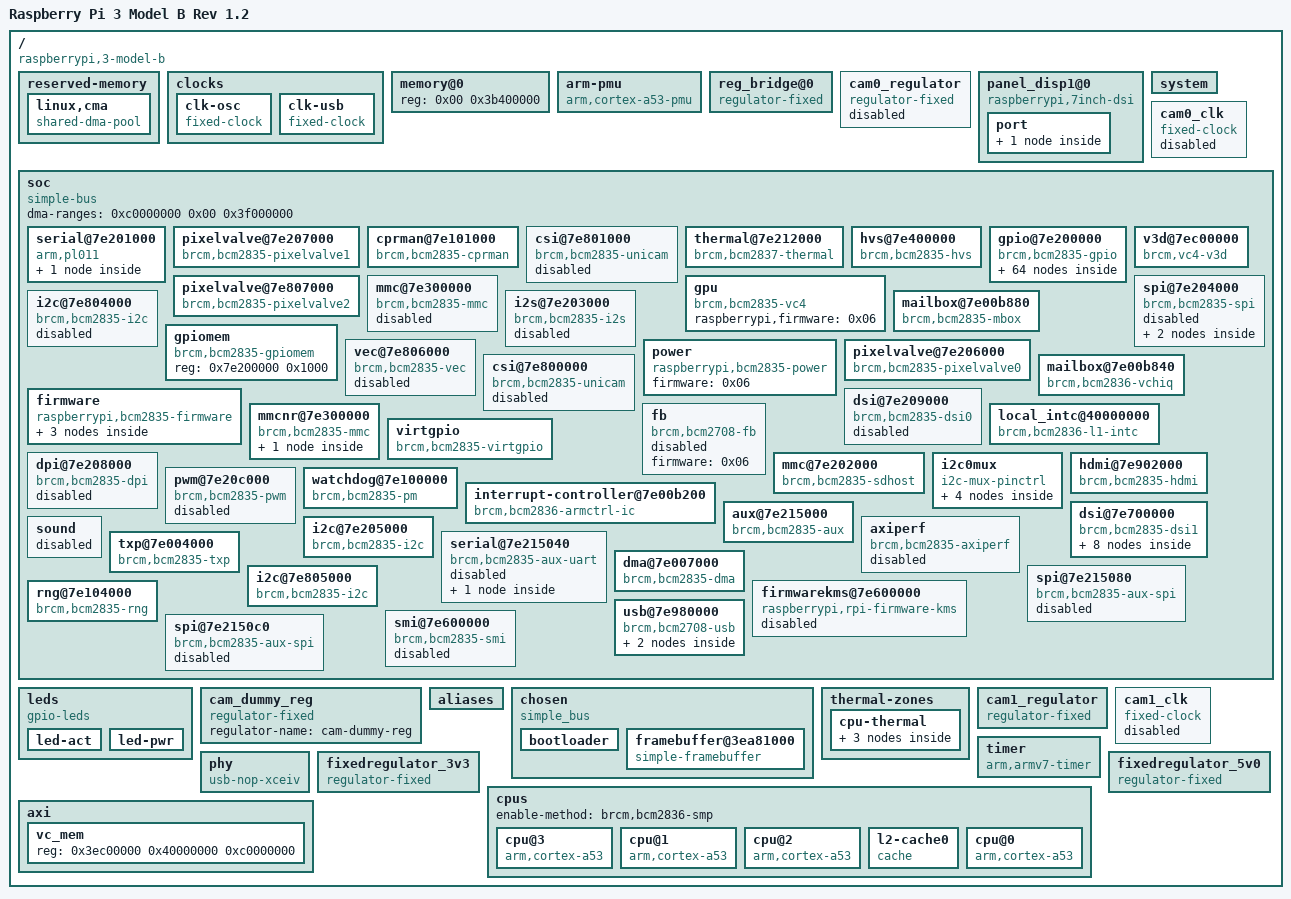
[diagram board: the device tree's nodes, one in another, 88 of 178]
/dts-v1/;

/ {
	compatible = "raspberrypi,3-model-b\0brcm,bcm2837";
	serial-number = "0000000004c159e7";
	model = "Raspberry Pi 3 Model B Rev 1.2";
	memreserve = <0x3b400000 0x4c00000>;
	interrupt-parent = <0x01>;
	#address-cells = <0x01>;
	#size-cells = <0x01>;

	reserved-memory {
		ranges;
		#address-cells = <0x01>;
		#size-cells = <0x01>;
		phandle = <0x38>;

		linux,cma {
			reusable;
			compatible = "shared-dma-pool";
			size = <0x10000000>;
			phandle = <0x39>;
			linux,cma-default;
		};
	};

	clocks {

		clk-osc {
			compatible = "fixed-clock";
			#clock-cells = <0x00>;
			phandle = <0x03>;
			clock-output-names = "osc";
			clock-frequency = <0x124f800>;
		};

		clk-usb {
			compatible = "fixed-clock";
			#clock-cells = <0x00>;
			phandle = <0x16>;
			clock-output-names = "otg";
			clock-frequency = <0x1c9c3800>;
		};
	};

	memory@0 {
		device_type = "memory";
		reg = <0x00 0x3b400000>;
	};

	__overrides__ {
		pwr_led_gpio = "\0\0\06gpios:4";
		cam0-led-ctrl;
		i2c1 = "\0\0\0+status";
		i2c_vc = [00 00 00 1c 73 74 61 74 75 73 00 00 00 00 2a 73 74 61 74 75 73 00];
		sd_overclock = "\0\0\0.brcm,overclock-50:0";
		sdio_overclock = "\0\0\0/brcm,overclock-50:0\0\0\0\00brcm,overclock-50:0";
		i2c0_baudrate = [00 00 00 1c 63 6c 6f 63 6b 2d 66 72 65 71 75 65 6e 63 79 3a 30 00];
		sd_pio_limit = "\0\0\0.brcm,pio-limit:0";
		act_led_trigger = "\0\0\05linux,default-trigger";
		audio = "\0\0\04bootargs{on='snd_bcm2835.enable_headphones=1 snd_bcm2835.enable_hdmi=1',off='snd_bcm2835.enable_headphones=0 snd_bcm2835.enable_hdmi=0'}";
		sd_debug = "\0\0\0.brcm,debug";
		cam0-pwdn-ctrl;
		cache_line_size;
		cam0-led;
		i2c1_baudrate = "\0\0\0+clock-frequency:0";
		spi = "\0\0\0)status";
		i2c_arm = "\0\0\0+status";
		sd = "\0\0\0.status";
		pwr_led_activelow = "\0\0\06gpios:8";
		uart0 = "\0\0\0&status";
		i2c2_iknowwhatimdoing = [00 00 00 1a 73 74 61 74 75 73 00];
		i2s = "\0\0\0(status";
		i2c0 = [00 00 00 1c 73 74 61 74 75 73 00 00 00 00 2a 73 74 61 74 75 73 00];
		arm_freq = "\0\0\0\"clock-frequency:0\0\0\0\0#clock-frequency:0\0\0\0\0$clock-frequency:0\0\0\0\0%clock-frequency:0";
		watchdog = "\0\0\0,status";
		krnbt = "\0\0\03status";
		i2c_baudrate = "\0\0\0+clock-frequency:0";
		i2c_vc_baudrate = [00 00 00 1c 63 6c 6f 63 6b 2d 66 72 65 71 75 65 6e 63 79 3a 30 00];
		sd_poll_once = "\0\0\0.non-removable?";
		axiperf = "\0\0\01status";
		act_led_activelow = "\0\0\05gpios:8";
		i2c2_baudrate = [00 00 00 1a 63 6c 6f 63 6b 2d 66 72 65 71 75 65 6e 63 79 3a 30 00];
		krnbt_baudrate = "\0\0\03max-speed:0";
		sd_force_pio = "\0\0\0.brcm,force-pio?";
		pwr_led_trigger = "\0\0\06linux,default-trigger";
		hdmi = "\0\0\02status";
		cam0-pwdn;
		uart1 = "\0\0\0'status";
		i2c_arm_baudrate = "\0\0\0+clock-frequency:0";
		random = "\0\0\0-status";
		act_led_gpio = "\0\0\05gpios:4";
		i2c = "\0\0\0+status";
	};

	arm-pmu {
		compatible = "arm,cortex-a53-pmu\0arm,cortex-a7-pmu";
		interrupt-parent = <0x18>;
		interrupts = <0x09 0x04>;
	};

	reg_bridge@0 {
		compatible = "regulator-fixed";
		enable-active-high;
		gpio = <0x9c 0x00 0x00>;
		phandle = <0x99>;
		vin-supply = <0x9c>;
		reg = <0x00>;
		regulator-name = "bridge_reg";
	};

	cam0_regulator {
		compatible = "regulator-fixed";
		enable-active-high;
		status = "disabled";
		phandle = <0x90>;
		regulator-name = "cam0-reg";
	};

	panel_disp1@0 {
		compatible = "raspberrypi,7inch-dsi\0simple-panel";
		phandle = <0x9e>;
		reg = <0x00>;
		backlight = <0x9c>;
		power-supply = <0x9c>;

		port {

			endpoint {
				remote-endpoint = <0x9d>;
				phandle = <0x9b>;
			};
		};
	};

	system {
		linux,serial = <0x00 0x4c159e7>;
		linux,revision = <0xa02082>;
	};

	__symbols__ {
		uart0_gpio14 = "/soc/gpio@7e200000/uart0_gpio14";
		pwm = "/soc/pwm@7e20c000";
		gpclk1_gpio5 = "/soc/gpio@7e200000/gpclk1_gpio5";
		clk_usb = "/clocks/clk-usb";
		pixelvalve0 = "/soc/pixelvalve@7e206000";
		minibt = "/soc/serial@7e215040/bluetooth";
		uart0_ctsrts_gpio30 = "/soc/gpio@7e200000/uart0_ctsrts_gpio30";
		uart1_ctsrts_gpio16 = "/soc/gpio@7e200000/uart1_ctsrts_gpio16";
		uart0_gpio32 = "/soc/gpio@7e200000/uart0_gpio32";
		intc = "/soc/interrupt-controller@7e00b200";
		spi2 = "/soc/spi@7e2150c0";
		i2c0if = "/soc/i2c@7e205000";
		jtag_gpio4 = "/soc/gpio@7e200000/jtag_gpio4";
		dsi1 = "/soc/dsi@7e700000";
		clocks = "/soc/cprman@7e101000";
		i2c1 = "/soc/i2c@7e804000";
		i2c_vc = "/soc/i2c0mux/i2c@0";
		alt0 = "/soc/gpio@7e200000/alt0";
		firmwarekms = "/soc/firmwarekms@7e600000";
		smi = "/soc/smi@7e600000";
		uart1_ctsrts_gpio42 = "/soc/gpio@7e200000/uart1_ctsrts_gpio42";
		spi0 = "/soc/spi@7e204000";
		bt = "/soc/serial@7e201000/bluetooth";
		thermal = "/soc/thermal@7e212000";
		vdd_5v0_reg = "/fixedregulator_5v0";
		vchiq = "/soc/mailbox@7e00b840";
		sdhost = "/soc/mmc@7e202000";
		aux = "/soc/aux@7e215000";
		cam0_regulator = "/cam0_regulator";
		gpio = "/soc/gpio@7e200000";
		gpclk0_gpio4 = "/soc/gpio@7e200000/gpclk0_gpio4";
		pwm0_gpio12 = "/soc/gpio@7e200000/pwm0_gpio12";
		pwm1_gpio19 = "/soc/gpio@7e200000/pwm1_gpio19";
		sdhci = "/soc/mmc@7e300000";
		pwm0_gpio40 = "/soc/gpio@7e200000/pwm0_gpio40";
		gpclk2_gpio43 = "/soc/gpio@7e200000/gpclk2_gpio43";
		cam1_reg = "/cam1_regulator";
		dpi = "/soc/dpi@7e208000";
		dpi_18bit_cpadhi_gpio2 = "/soc/gpio@7e200000/dpi_18bit_cpadhi_gpio2";
		v3d = "/soc/v3d@7ec00000";
		vdd_3v3_reg = "/fixedregulator_3v3";
		uart1_ctsrts_gpio30 = "/soc/gpio@7e200000/uart1_ctsrts_gpio30";
		gpioout = "/soc/gpio@7e200000/gpioout";
		dma = "/soc/dma@7e007000";
		spidev1 = "/soc/spi@7e204000/spidev@1";
		mmcnr = "/soc/mmcnr@7e300000";
		spi0_gpio35 = "/soc/gpio@7e200000/spi0_gpio35";
		vc4 = "/soc/gpu";
		firmware_clocks = "/soc/firmware/clocks";
		pwm1_gpio45 = "/soc/gpio@7e200000/pwm1_gpio45";
		cpu3 = "/cpus/cpu@3";
		dpi_18bit_cpadhi_gpio0 = "/soc/gpio@7e200000/dpi_18bit_cpadhi_gpio0";
		cam0_clk = "/cam0_clk";
		pcm_gpio28 = "/soc/gpio@7e200000/pcm_gpio28";
		dpi_gpio0 = "/soc/gpio@7e200000/dpi_gpio0";
		power = "/soc/power";
		soc = "/soc";
		i2c0_gpio0 = "/soc/gpio@7e200000/i2c0_gpio0";
		pcm_gpio18 = "/soc/gpio@7e200000/pcm_gpio18";
		leds = "/leds";
		thermal_trips = "/thermal-zones/cpu-thermal/trips";
		csi1 = "/soc/csi@7e801000";
		i2s_pins = "/soc/gpio@7e200000/i2s";
		cam_dummy_reg = "/cam_dummy_reg";
		firmware = "/soc/firmware";
		cpu1 = "/cpus/cpu@1";
		mmc = "/soc/mmc@7e300000";
		l2 = "/cpus/l2-cache0";
		dpi_18bit_gpio2 = "/soc/gpio@7e200000/dpi_18bit_gpio2";
		usbphy = "/phy";
		pixelvalve1 = "/soc/pixelvalve@7e207000";
		spi = "/soc/spi@7e204000";
		spi0_pins = "/soc/gpio@7e200000/spi0_pins";
		i2c_arm = "/soc/i2c@7e804000";
		chosen = "/chosen";
		clk_osc = "/clocks/clk-osc";
		ethernet = "/soc/usb@7e980000/usb1@1/ethernet@1";
		uart0 = "/soc/serial@7e201000";
		pwm1_gpio13 = "/soc/gpio@7e200000/pwm1_gpio13";
		i2c1_pins = "/soc/gpio@7e200000/i2c1";
		rmem = "/reserved-memory";
		cpu_thermal = "/thermal-zones/cpu-thermal";
		fb = "/soc/fb";
		pwm1_gpio41 = "/soc/gpio@7e200000/pwm1_gpio41";
		txp = "/soc/txp@7e004000";
		dpi_18bit_gpio0 = "/soc/gpio@7e200000/dpi_18bit_gpio0";
		spi0_gpio7 = "/soc/gpio@7e200000/spi0_gpio7";
		i2c2 = "/soc/i2c@7e805000";
		uart1_pins = "/soc/gpio@7e200000/uart1_pins";
		i2c1_gpio44 = "/soc/gpio@7e200000/i2c1_gpio44";
		cma = "/reserved-memory/linux,cma";
		i2c0_gpio28 = "/soc/gpio@7e200000/i2c0_gpio28";
		i2c_slave_gpio18 = "/soc/gpio@7e200000/i2c_slave_gpio18";
		cam1_clk = "/cam1_clk";
		i2s = "/soc/i2s@7e203000";
		emmc_gpio48 = "/soc/gpio@7e200000/emmc_gpio48";
		spi1 = "/soc/spi@7e215080";
		virtgpio = "/soc/virtgpio";
		usb = "/soc/usb@7e980000";
		dsi0 = "/soc/dsi@7e209000";
		i2c1_gpio2 = "/soc/gpio@7e200000/i2c1_gpio2";
		expgpio = "/soc/firmware/expgpio";
		uart0_ctsrts_gpio38 = "/soc/gpio@7e200000/uart0_ctsrts_gpio38";
		pm = "/soc/watchdog@7e100000";
		audio_pins = "/soc/gpio@7e200000/audio_pins";
		i2c0 = "/soc/i2c0mux/i2c@0";
		brcmf = "/soc/mmcnr@7e300000/wifi@1";
		spi1_gpio16 = "/soc/gpio@7e200000/spi1_gpio16";
		i2c0mux = "/soc/i2c0mux";
		i2c_csi_dsi = "/soc/i2c0mux/i2c@1";
		i2c0_pins = "/soc/gpio@7e200000/i2c0";
		pwr_led = "/leds/led-pwr";
		watchdog = "/soc/watchdog@7e100000";
		jtag_gpio22 = "/soc/gpio@7e200000/jtag_gpio22";
		spi2_gpio40 = "/soc/gpio@7e200000/spi2_gpio40";
		uart0_pins = "/soc/gpio@7e200000/uart0_pins";
		vec = "/soc/vec@7e806000";
		local_intc = "/soc/local_intc@40000000";
		i2c0_gpio44 = "/soc/gpio@7e200000/i2c0_gpio44";
		axiperf = "/soc/axiperf";
		spi0_cs_pins = "/soc/gpio@7e200000/spi0_cs_pins";
		sound = "/soc/sound";
		hvs = "/soc/hvs@7e400000";
		uart0_ctsrts_gpio16 = "/soc/gpio@7e200000/uart0_ctsrts_gpio16";
		act_led = "/leds/led-act";
		gpclk2_gpio6 = "/soc/gpio@7e200000/gpclk2_gpio6";
		spidev0 = "/soc/spi@7e204000/spidev@0";
		sdhost_gpio48 = "/soc/gpio@7e200000/sdhost_gpio48";
		bt_pins = "/soc/gpio@7e200000/bt_pins";
		dpi_16bit_gpio2 = "/soc/gpio@7e200000/dpi_16bit_gpio2";
		emmc_gpio34 = "/soc/gpio@7e200000/emmc_gpio34";
		gpclk1_gpio44 = "/soc/gpio@7e200000/gpclk1_gpio44";
		uart1_gpio14 = "/soc/gpio@7e200000/uart1_gpio14";
		cooling_maps = "/thermal-zones/cpu-thermal/cooling-maps";
		uart0_gpio36 = "/soc/gpio@7e200000/uart0_gpio36";
		sdio_pins = "/soc/gpio@7e200000/sdio_pins";
		dpi_16bit_cpadhi_gpio2 = "/soc/gpio@7e200000/dpi_16bit_cpadhi_gpio2";
		cpus = "/cpus";
		cpu2 = "/cpus/cpu@2";
		uart1_gpio32 = "/soc/gpio@7e200000/uart1_gpio32";
		hdmi = "/soc/hdmi@7e902000";
		pixelvalve2 = "/soc/pixelvalve@7e807000";
		pwm0_gpio18 = "/soc/gpio@7e200000/pwm0_gpio18";
		dpi_16bit_gpio0 = "/soc/gpio@7e200000/dpi_16bit_gpio0";
		gpclk1_gpio42 = "/soc/gpio@7e200000/gpclk1_gpio42";
		mailbox = "/soc/mailbox@7e00b880";
		uart1_gpio40 = "/soc/gpio@7e200000/uart1_gpio40";
		emmc_gpio22 = "/soc/gpio@7e200000/emmc_gpio22";
		uart1 = "/soc/serial@7e215040";
		dpi_16bit_cpadhi_gpio0 = "/soc/gpio@7e200000/dpi_16bit_cpadhi_gpio0";
		csi0 = "/soc/csi@7e800000";
		cam0_reg = "/cam_dummy_reg";
		random = "/soc/rng@7e104000";
		i2c = "/soc/i2c@7e804000";
		cpu0 = "/cpus/cpu@0";
		vcio = "/soc/firmware/vcio";
	};

	cam0_clk {
		compatible = "fixed-clock";
		status = "disabled";
		#clock-cells = <0x00>;
		phandle = <0x91>;
	};

	soc {
		compatible = "simple-bus";
		ranges = <0x7e000000 0x3f000000 0x1000000 0x40000000 0x40000000 0x1000>;
		#address-cells = <0x01>;
		#size-cells = <0x01>;
		phandle = <0x3d>;
		dma-ranges = <0xc0000000 0x00 0x3f000000>;

		serial@7e201000 {
			compatible = "arm,pl011\0arm,primecell";
			clocks = <0x08 0x13 0x08 0x14>;
			clock-names = "uartclk\0apb_pclk";
			status = "okay";
			interrupts = <0x02 0x19>;
			skip-init;
			phandle = <0x26>;
			arm,primecell-periphid = <0x241011>;
			reg = <0x7e201000 0x200>;
			pinctrl-0 = <0x09 0x0a>;
			cts-event-workaround;
			pinctrl-names = "default";

			bluetooth {
				compatible = "brcm,bcm43438-bt";
				shutdown-gpios = <0x0b 0x00 0x00>;
				max-speed = <0xe1000>;
				status = "disabled";
				phandle = <0x33>;
			};
		};

		pixelvalve@7e207000 {
			compatible = "brcm,bcm2835-pixelvalve1";
			status = "okay";
			interrupts = <0x02 0x0e>;
			phandle = <0x7d>;
			reg = <0x7e207000 0x100>;
		};

		cprman@7e101000 {
			compatible = "brcm,bcm2835-cprman";
			clocks = <0x03 0x04 0x00 0x04 0x01 0x04 0x02 0x05 0x00 0x05 0x01 0x05 0x02>;
			firmware = <0x06>;
			#clock-cells = <0x01>;
			phandle = <0x08>;
			claim-clocks = <0x22 0x23 0x0f 0x10>;
			reg = <0x7e101000 0x2000>;
		};

		csi@7e801000 {
			power-domains = <0x11 0x0d>;
			compatible = "brcm,bcm2835-unicam";
			clocks = <0x08 0x2e 0x19 0x04>;
			clock-names = "lp\0vpu";
			status = "disabled";
			#address-cells = <0x01>;
			interrupts = <0x02 0x07>;
			brcm,num-data-lanes = <0x02>;
			#size-cells = <0x00>;
			#clock-cells = <0x01>;
			phandle = <0x86>;
			reg = <0x7e801000 0x800 0x7e802004 0x04>;
		};

		thermal@7e212000 {
			compatible = "brcm,bcm2837-thermal";
			clocks = <0x08 0x1b>;
			#thermal-sensor-cells = <0x00>;
			status = "okay";
			phandle = <0x02>;
			reg = <0x7e212000 0x08>;
		};

		hvs@7e400000 {
			compatible = "brcm,bcm2835-hvs";
			status = "okay";
			interrupts = <0x02 0x01>;
			phandle = <0x79>;
			reg = <0x7e400000 0x6000>;
		};

		gpio@7e200000 {
			compatible = "brcm,bcm2835-gpio";
			gpio-line-names = "ID_SDA\0ID_SCL\0SDA1\0SCL1\0GPIO_GCLK\0GPIO5\0GPIO6\0SPI_CE1_N\0SPI_CE0_N\0SPI_MISO\0SPI_MOSI\0SPI_SCLK\0GPIO12\0GPIO13\0TXD1\0RXD1\0GPIO16\0GPIO17\0GPIO18\0GPIO19\0GPIO20\0GPIO21\0GPIO22\0GPIO23\0GPIO24\0GPIO25\0GPIO26\0GPIO27\0NC\0LAN_RUN_BOOT\0CTS0\0RTS0\0TXD0\0RXD0\0SD1_CLK\0SD1_CMD\0SD1_DATA0\0SD1_DATA1\0SD1_DATA2\0SD1_DATA3\0PWM0_OUT\0PWM1_OUT\0ETH_CLK\0WIFI_CLK\0SDA0\0SCL0\0SMPS_SCL\0SMPS_SDA\0SD_CLK_R\0SD_CMD_R\0SD_DATA0_R\0SD_DATA1_R\0SD_DATA2_R\0SD_DATA3_R";
			gpio-controller;
			gpio-ranges = <0x07 0x00 0x00 0x36>;
			#interrupt-cells = <0x02>;
			interrupts = <0x02 0x11 0x02 0x12>;
			phandle = <0x07>;
			reg = <0x7e200000 0xb4>;
			#gpio-cells = <0x02>;
			pinctrl-names = "default";
			interrupt-controller;

			uart0_gpio14 {
				brcm,pins = <0x0e 0x0f>;
				phandle = <0x52>;
				brcm,function = <0x04>;
			};

			gpclk1_gpio5 {
				brcm,pins = <0x05>;
				phandle = <0x43>;
				brcm,function = <0x04>;
			};

			uart0_ctsrts_gpio30 {
				brcm,pins = <0x1e 0x1f>;
				phandle = <0x54>;
				brcm,pull = <0x02 0x00>;
				brcm,function = <0x07>;
			};

			uart1_ctsrts_gpio16 {
				brcm,pins = <0x10 0x11>;
				phandle = <0x59>;
				brcm,function = <0x02>;
			};

			uart0_gpio32 {
				brcm,pins = <0x20 0x21>;
				phandle = <0x55>;
				brcm,pull = <0x00 0x02>;
				brcm,function = <0x07>;
			};

			jtag_gpio4 {
				brcm,pins = <0x04 0x05 0x06 0x0c 0x0d>;
				phandle = <0x5f>;
				brcm,function = <0x02>;
			};

			i2c1 {
				brcm,pins = <0x02 0x03>;
				phandle = <0x15>;
				brcm,function = <0x04>;
			};

			alt0 {
				brcm,pins = <0x04 0x05 0x07 0x08 0x09 0x0a 0x0b>;
				phandle = <0x70>;
				brcm,function = <0x04>;
			};

			uart1_ctsrts_gpio42 {
				brcm,pins = <0x2a 0x2b>;
				phandle = <0x5d>;
				brcm,function = <0x02>;
			};

			gpclk0_gpio4 {
				brcm,pins = <0x04>;
				phandle = <0x42>;
				brcm,function = <0x04>;
			};

			pwm0_gpio12 {
				brcm,pins = <0x0c>;
				phandle = <0x60>;
				brcm,function = <0x04>;
			};

			pwm1_gpio19 {
				brcm,pins = <0x13>;
				phandle = <0x64>;
				brcm,function = <0x02>;
			};

			pwm0_gpio40 {
				brcm,pins = <0x28>;
				phandle = <0x62>;
				brcm,function = <0x04>;
			};

			gpclk2_gpio43 {
				brcm,pins = <0x2b>;
				phandle = <0x47>;
				brcm,pull = <0x00>;
				brcm,function = <0x04>;
			};

			dpi_18bit_cpadhi_gpio2 {
				brcm,pins = <0x02 0x03 0x04 0x05 0x06 0x07 0x08 0x09 0x0c 0x0d 0x0e 0x0f 0x10 0x11 0x14 0x15 0x16 0x17 0x18 0x19>;
				phandle = <0x68>;
				brcm,function = <0x06>;
			};

			uart1_ctsrts_gpio30 {
				brcm,pins = <0x1e 0x1f>;
				phandle = <0x5b>;
				brcm,function = <0x02>;
			};

			gpioout {
				brcm,pins = <0x06>;
				phandle = <0x6f>;
				brcm,function = <0x01>;
			};

			spi0_gpio35 {
				brcm,pins = <0x23 0x24 0x25 0x26 0x27>;
				phandle = <0x4f>;
				brcm,function = <0x04>;
			};

			pwm1_gpio45 {
				brcm,pins = <0x2d>;
				phandle = <0x66>;
				brcm,function = <0x04>;
			};

			dpi_18bit_cpadhi_gpio0 {
				brcm,pins = <0x00 0x01 0x02 0x03 0x04 0x05 0x06 0x07 0x08 0x09 0x0c 0x0d 0x0e 0x0f 0x10 0x11 0x14 0x15 0x16 0x17 0x18 0x19>;
				phandle = <0x67>;
				brcm,pull = <0x00>;
				brcm,function = <0x06>;
			};

			pcm_gpio28 {
				brcm,pins = <0x1c 0x1d 0x1e 0x1f>;
				phandle = <0x4d>;
				brcm,function = <0x06>;
			};

			dpi_gpio0 {
				brcm,pins = <0x00 0x01 0x02 0x03 0x04 0x05 0x06 0x07 0x08 0x09 0x0a 0x0b 0x0c 0x0d 0x0e 0x0f 0x10 0x11 0x12 0x13 0x14 0x15 0x16 0x17 0x18 0x19 0x1a 0x1b>;
				phandle = <0x3f>;
				brcm,function = <0x06>;
			};

			i2c0_gpio0 {
				brcm,pins = <0x00 0x01>;
				phandle = <0x1d>;
				brcm,function = <0x04>;
			};

			pcm_gpio18 {
				brcm,pins = <0x12 0x13 0x14 0x15>;
				phandle = <0x4c>;
				brcm,function = <0x04>;
			};

			dpi_18bit_gpio2 {
				brcm,pins = <0x02 0x03 0x04 0x05 0x06 0x07 0x08 0x09 0x0a 0x0b 0x0c 0x0d 0x0e 0x0f 0x10 0x11 0x12 0x13 0x14 0x15>;
				phandle = <0x6a>;
				brcm,function = <0x06>;
			};

			spi0_pins {
				brcm,pins = <0x09 0x0a 0x0b>;
				phandle = <0x0f>;
				brcm,function = <0x04>;
			};

			pwm1_gpio13 {
				brcm,pins = <0x0d>;
				phandle = <0x63>;
				brcm,function = <0x04>;
			};

			pwm1_gpio41 {
				brcm,pins = <0x29>;
				phandle = <0x65>;
				brcm,function = <0x04>;
			};

			dpi_18bit_gpio0 {
				brcm,pins = <0x00 0x01 0x02 0x03 0x04 0x05 0x06 0x07 0x08 0x09 0x0a 0x0b 0x0c 0x0d 0x0e 0x0f 0x10 0x11 0x12 0x13 0x14 0x15>;
				phandle = <0x69>;
				brcm,function = <0x06>;
			};

			spi0_gpio7 {
				brcm,pins = <0x07 0x08 0x09 0x0a 0x0b>;
				phandle = <0x4e>;
				brcm,function = <0x04>;
			};

			uart1_pins {
				brcm,pins;
				phandle = <0x13>;
				brcm,pull;
				brcm,function;
			};

			i2c1_gpio44 {
				brcm,pins = <0x2c 0x2d>;
				phandle = <0x4a>;
				brcm,function = <0x06>;
			};

			i2c0_gpio28 {
				brcm,pins = <0x1c 0x1d>;
				phandle = <0x48>;
				brcm,function = <0x04>;
			};

			i2c_slave_gpio18 {
				brcm,pins = <0x12 0x13 0x14 0x15>;
				phandle = <0x5e>;
				brcm,function = <0x07>;
			};

			i2s {
				brcm,pins = <0x12 0x13 0x14 0x15>;
				phandle = <0x0e>;
				brcm,function = <0x04>;
			};

			emmc_gpio48 {
				brcm,pins = <0x30 0x31 0x32 0x33 0x34 0x35>;
				phandle = <0x14>;
				brcm,function = <0x07>;
			};

			i2c1_gpio2 {
				brcm,pins = <0x02 0x03>;
				phandle = <0x49>;
				brcm,function = <0x04>;
			};

			uart0_ctsrts_gpio38 {
				brcm,pins = <0x26 0x27>;
				phandle = <0x57>;
				brcm,function = <0x06>;
			};

			audio_pins {
				brcm,pins = <0x28 0x29>;
				phandle = <0x20>;
				brcm,pull = <0x00>;
				brcm,function = <0x04>;
			};

			i2c0 {
				brcm,pins = <0x00 0x01>;
				phandle = <0x71>;
				brcm,function = <0x04>;
			};

			spi1_gpio16 {
				brcm,pins = <0x10 0x11 0x12 0x13 0x14 0x15>;
				phandle = <0x50>;
				brcm,function = <0x03>;
			};

			jtag_gpio22 {
				brcm,pins = <0x16 0x17 0x18 0x19 0x1a 0x1b>;
				phandle = <0x4b>;
				brcm,function = <0x03>;
			};

			spi2_gpio40 {
				brcm,pins = <0x28 0x29 0x2a 0x2b 0x2c 0x2d>;
				phandle = <0x51>;
				brcm,function = <0x03>;
			};

			uart0_pins {
				brcm,pins = <0x20 0x21>;
				phandle = <0x09>;
				brcm,pull = <0x00 0x02>;
				brcm,function = <0x07>;
			};

			i2c0_gpio44 {
				brcm,pins = <0x2c 0x2d>;
				phandle = <0x1e>;
				brcm,function = <0x05>;
			};

			spi0_cs_pins {
				brcm,pins = <0x08 0x07>;
				phandle = <0x10>;
				brcm,function = <0x01>;
			};

			uart0_ctsrts_gpio16 {
				brcm,pins = <0x10 0x11>;
				phandle = <0x53>;
				brcm,function = <0x07>;
			};

			gpclk2_gpio6 {
				brcm,pins = <0x06>;
				phandle = <0x46>;
				brcm,function = <0x04>;
			};

			sdhost_gpio48 {
				brcm,pins = <0x30 0x31 0x32 0x33 0x34 0x35>;
				phandle = <0x0d>;
				brcm,function = <0x04>;
			};

			bt_pins {
				brcm,pins = <0x2b>;
				phandle = <0x0a>;
				brcm,pull = <0x00>;
				brcm,function = <0x04>;
			};

			dpi_16bit_gpio2 {
				brcm,pins = <0x02 0x03 0x04 0x05 0x06 0x07 0x08 0x09 0x0a 0x0b 0x0c 0x0d 0x0e 0x0f 0x10 0x11 0x12 0x13>;
				phandle = <0x6c>;
				brcm,function = <0x06>;
			};

			emmc_gpio34 {
				brcm,pins = <0x22 0x23 0x24 0x25 0x26 0x27>;
				phandle = <0x41>;
				brcm,pull = <0x00 0x02 0x02 0x02 0x02 0x02>;
				brcm,function = <0x07>;
			};

			gpclk1_gpio44 {
				brcm,pins = <0x2c>;
				phandle = <0x45>;
				brcm,function = <0x04>;
			};

			uart1_gpio14 {
				brcm,pins = <0x0e 0x0f>;
				phandle = <0x58>;
				brcm,function = <0x02>;
			};

			uart0_gpio36 {
				brcm,pins = <0x24 0x25>;
				phandle = <0x56>;
				brcm,function = <0x06>;
			};

			sdio_pins {
				brcm,pins = <0x22 0x23 0x24 0x25 0x26 0x27>;
				phandle = <0x1b>;
				brcm,pull = <0x00 0x02 0x02 0x02 0x02 0x02>;
				brcm,function = <0x07>;
			};

			dpi_16bit_cpadhi_gpio2 {
				brcm,pins = <0x02 0x03 0x04 0x05 0x06 0x07 0x08 0x0c 0x0d 0x0e 0x0f 0x10 0x11 0x14 0x15 0x16 0x17 0x18>;
				phandle = <0x6e>;
				brcm,function = <0x06>;
			};

			uart1_gpio32 {
				brcm,pins = <0x20 0x21>;
				phandle = <0x5a>;
				brcm,function = <0x02>;
			};

			pwm0_gpio18 {
				brcm,pins = <0x12>;
				phandle = <0x61>;
				brcm,function = <0x02>;
			};

			dpi_16bit_gpio0 {
				brcm,pins = <0x00 0x01 0x02 0x03 0x04 0x05 0x06 0x07 0x08 0x09 0x0a 0x0b 0x0c 0x0d 0x0e 0x0f 0x10 0x11 0x12 0x13>;
				phandle = <0x6b>;
				brcm,function = <0x06>;
			};

			gpclk1_gpio42 {
				brcm,pins = <0x2a>;
				phandle = <0x44>;
				brcm,function = <0x04>;
			};

			uart1_gpio40 {
				brcm,pins = <0x28 0x29>;
				phandle = <0x5c>;
				brcm,function = <0x02>;
			};

			emmc_gpio22 {
				brcm,pins = <0x16 0x17 0x18 0x19 0x1a 0x1b>;
				phandle = <0x40>;
				brcm,function = <0x07>;
			};

			dpi_16bit_cpadhi_gpio0 {
				brcm,pins = <0x00 0x01 0x02 0x03 0x04 0x05 0x06 0x07 0x08 0x0c 0x0d 0x0e 0x0f 0x10 0x11 0x14 0x15 0x16 0x17 0x18>;
				phandle = <0x6d>;
				brcm,function = <0x06>;
			};
		};

		pixelvalve@7e807000 {
			compatible = "brcm,bcm2835-pixelvalve2";
			status = "okay";
			interrupts = <0x02 0x0a>;
			phandle = <0x7f>;
			reg = <0x7e807000 0x100>;
		};

		v3d@7ec00000 {
			power-domains = <0x11 0x0a>;
			compatible = "brcm,vc4-v3d";
			status = "okay";
			interrupts = <0x01 0x0a>;
			phandle = <0x80>;
			reg = <0x7ec00000 0x1000>;
		};

		gpu {
			compatible = "brcm,bcm2835-vc4";
			status = "okay";
			phandle = <0x81>;
			raspberrypi,firmware = <0x06>;
		};

		mmc@7e300000 {
			compatible = "brcm,bcm2835-mmc\0brcm,bcm2835-sdhci";
			clocks = <0x08 0x1c>;
			status = "disabled";
			interrupts = <0x02 0x1e>;
			brcm,overclock-50 = <0x00>;
			bus-width = <0x04>;
			dma-names = "rx-tx";
			phandle = <0x2f>;
			reg = <0x7e300000 0x100>;
			pinctrl-0 = <0x14>;
			dmas = <0x0c 0x0b>;
			pinctrl-names = "default";
		};

		spi@7e204000 {
			compatible = "brcm,bcm2835-spi";
			clocks = <0x08 0x14>;
			status = "disabled";
			#address-cells = <0x01>;
			interrupts = <0x02 0x16>;
			cs-gpios = <0x07 0x08 0x01 0x07 0x07 0x01>;
			#size-cells = <0x00>;
			dma-names = "tx\0rx";
			phandle = <0x29>;
			reg = <0x7e204000 0x200>;
			pinctrl-0 = <0x0f 0x10>;
			dmas = <0x0c 0x06 0x0c 0x07>;
			pinctrl-names = "default";

			spidev@1 {
				compatible = "spidev";
				#address-cells = <0x01>;
				#size-cells = <0x00>;
				phandle = <0x73>;
				reg = <0x01>;
				spi-max-frequency = <0x7735940>;
			};

			spidev@0 {
				compatible = "spidev";
				#address-cells = <0x01>;
				#size-cells = <0x00>;
				phandle = <0x72>;
				reg = <0x00>;
				spi-max-frequency = <0x7735940>;
			};
		};

		i2c@7e804000 {
			compatible = "brcm,bcm2835-i2c";
			clocks = <0x08 0x14>;
			status = "disabled";
			#address-cells = <0x01>;
			interrupts = <0x02 0x15>;
			#size-cells = <0x00>;
			phandle = <0x2b>;
			reg = <0x7e804000 0x1000>;
			clock-frequency = <0x186a0>;
			pinctrl-0 = <0x15>;
			pinctrl-names = "default";
		};

		i2s@7e203000 {
			compatible = "brcm,bcm2835-i2s";
			clocks = <0x08 0x1f>;
			#sound-dai-cells = <0x00>;
			status = "disabled";
			dma-names = "tx\0rx";
			phandle = <0x28>;
			reg = <0x7e203000 0x24>;
			pinctrl-0 = <0x0e>;
			dmas = <0x0c 0x02 0x0c 0x03>;
			pinctrl-names = "default";
		};

		mailbox@7e00b880 {
			compatible = "brcm,bcm2835-mbox";
			#mbox-cells = <0x00>;
			interrupts = <0x00 0x01>;
			phandle = <0x1f>;
			reg = <0x7e00b880 0x40>;
		};

		gpiomem {
			compatible = "brcm,bcm2835-gpiomem";
			reg = <0x7e200000 0x1000>;
		};

		vec@7e806000 {
			power-domains = <0x11 0x07>;
			compatible = "brcm,bcm2835-vec";
			clocks = <0x19 0x0f>;
			status = "disabled";
			interrupts = <0x02 0x1b>;
			phandle = <0x7e>;
			reg = <0x7e806000 0x1000>;
		};

		power {
			compatible = "raspberrypi,bcm2835-power";
			firmware = <0x06>;
			phandle = <0x11>;
			#power-domain-cells = <0x01>;
		};

		pixelvalve@7e206000 {
			compatible = "brcm,bcm2835-pixelvalve0";
			status = "okay";
			interrupts = <0x02 0x0d>;
			phandle = <0x7c>;
			reg = <0x7e206000 0x100>;
		};

		csi@7e800000 {
			power-domains = <0x11 0x0c>;
			compatible = "brcm,bcm2835-unicam";
			clocks = <0x08 0x2d 0x19 0x04>;
			clock-names = "lp\0vpu";
			status = "disabled";
			#address-cells = <0x01>;
			interrupts = <0x02 0x06>;
			#size-cells = <0x00>;
			#clock-cells = <0x01>;
			phandle = <0x85>;
			reg = <0x7e800000 0x800 0x7e802000 0x04>;
		};

		mailbox@7e00b840 {
			compatible = "brcm,bcm2836-vchiq\0brcm,bcm2835-vchiq";
			interrupts = <0x00 0x02>;
			phandle = <0x8a>;
			reg = <0x7e00b840 0x3c>;
			pinctrl-0 = <0x20>;
			pinctrl-names = "default";
		};

		firmware {
			compatible = "raspberrypi,bcm2835-firmware\0simple-mfd";
			#address-cells = <0x01>;
			mboxes = <0x1f>;
			#size-cells = <0x01>;
			phandle = <0x06>;
			dma-ranges;

			clocks {
				compatible = "raspberrypi,firmware-clocks";
				#clock-cells = <0x01>;
				phandle = <0x19>;
			};

			expgpio {
				compatible = "raspberrypi,firmware-gpio";
				gpio-line-names = "BT_ON\0WL_ON\0STATUS_LED\0LAN_RUN\0HDMI_HPD_N\0CAM_GPIO0\0CAM_GPIO1\0PWR_LOW_N";
				gpio-controller;
				status = "okay";
				phandle = <0x0b>;
				#gpio-cells = <0x02>;
			};

			vcio {
				compatible = "raspberrypi,vcio";
				phandle = <0x89>;
			};
		};

		dsi@7e209000 {
			power-domains = <0x11 0x11>;
			compatible = "brcm,bcm2835-dsi0";
			clocks = <0x08 0x20 0x08 0x2f 0x08 0x31>;
			clock-names = "phy\0escape\0pixel";
			status = "disabled";
			#address-cells = <0x01>;
			interrupts = <0x02 0x04>;
			#size-cells = <0x00>;
			#clock-cells = <0x01>;
			phandle = <0x04>;
			reg = <0x7e209000 0x78>;
			clock-output-names = "dsi0_byte\0dsi0_ddr2\0dsi0_ddr";
		};

		mmcnr@7e300000 {
			compatible = "brcm,bcm2835-mmc\0brcm,bcm2835-sdhci";
			clocks = <0x08 0x1c>;
			status = "okay";
			#address-cells = <0x01>;
			interrupts = <0x02 0x1e>;
			brcm,overclock-50 = <0x00>;
			bus-width = <0x04>;
			#size-cells = <0x00>;
			dma-names = "rx-tx";
			phandle = <0x30>;
			reg = <0x7e300000 0x100>;
			pinctrl-0 = <0x1b>;
			dmas = <0x0c 0x0b>;
			non-removable;
			pinctrl-names = "default";

			wifi@1 {
				compatible = "brcm,bcm4329-fmac";
				phandle = <0x82>;
				reg = <0x01>;
			};
		};

		fb {
			compatible = "brcm,bcm2708-fb";
			firmware = <0x06>;
			status = "disabled";
			phandle = <0x8b>;
		};

		local_intc@40000000 {
			compatible = "brcm,bcm2836-l1-intc";
			#interrupt-cells = <0x02>;
			interrupt-parent = <0x18>;
			phandle = <0x18>;
			reg = <0x40000000 0x100>;
			interrupt-controller;
		};

		virtgpio {
			compatible = "brcm,bcm2835-virtgpio";
			gpio-controller;
			firmware = <0x06>;
			status = "okay";
			phandle = <0x37>;
			#gpio-cells = <0x02>;
		};

		dpi@7e208000 {
			compatible = "brcm,bcm2835-dpi";
			clocks = <0x08 0x14 0x08 0x2c>;
			clock-names = "core\0pixel";
			status = "disabled";
			phandle = <0x74>;
			reg = <0x7e208000 0x8c>;
		};

		mmc@7e202000 {
			compatible = "brcm,bcm2835-sdhost";
			clocks = <0x08 0x14>;
			brcm,pio-limit = <0x01>;
			firmware = <0x06>;
			status = "okay";
			interrupts = <0x02 0x18>;
			brcm,overclock-50 = <0x00>;
			bus-width = <0x04>;
			dma-names = "rx-tx";
			phandle = <0x2e>;
			reg = <0x7e202000 0x100>;
			pinctrl-0 = <0x0d>;
			dmas = <0x0c 0x2000000d>;
			pinctrl-names = "default";
		};

		i2c0mux {
			compatible = "i2c-mux-pinctrl";
			pinctrl-1 = <0x1e>;
			status = "okay";
			#address-cells = <0x01>;
			i2c-parent = <0x1c>;
			#size-cells = <0x00>;
			phandle = <0x2a>;
			pinctrl-0 = <0x1d>;
			pinctrl-names = "i2c0\0i2c_csi_dsi";

			i2c@0 {
				#address-cells = <0x01>;
				#size-cells = <0x00>;
				phandle = <0x87>;
				reg = <0x00>;
			};

			i2c@1 {
				status = "okay";
				#address-cells = <0x01>;
				#size-cells = <0x00>;
				phandle = <0x88>;
				reg = <0x01>;

				reg_display@45 {
					compatible = "raspberrypi,7inch-touchscreen-panel-regulator";
					gpio-controller;
					phandle = <0x9c>;
					reg = <0x45>;
					#gpio-cells = <0x02>;
				};

				ts@38 {
					touchscreen-size-y = <0x1e0>;
					reset-gpio = <0x9c 0x01 0x01>;
					compatible = "edt,edt-ft5506";
					touchscreen-inverted-y;
					vcc-supply = <0x9c>;
					touchscreen-size-x = <0x320>;
					phandle = <0x97>;
					reg = <0x38>;
					touchscreen-inverted-x;
				};
			};
		};

		hdmi@7e902000 {
			power-domains = <0x11 0x05>;
			compatible = "brcm,bcm2835-hdmi";
			clocks = <0x19 0x09 0x19 0x0d>;
			reg-names = "hdmi\0hd";
			clock-names = "pixel\0hdmi";
			ddc = <0x1a>;
			status = "okay";
			interrupts = <0x02 0x08 0x02 0x09>;
			dma-names = "audio-rx";
			phandle = <0x32>;
			hpd-gpios = <0x0b 0x04 0x01>;
			reg = <0x7e902000 0x600 0x7e808000 0x100>;
			dmas = <0x0c 0x9000011>;
		};

		pwm@7e20c000 {
			compatible = "brcm,bcm2835-pwm";
			clocks = <0x08 0x1e>;
			status = "disabled";
			assigned-clock-rates = <0x989680>;
			assigned-clocks = <0x08 0x1e>;
			phandle = <0x78>;
			reg = <0x7e20c000 0x28>;
			#pwm-cells = <0x02>;
		};

		watchdog@7e100000 {
			compatible = "brcm,bcm2835-pm\0brcm,bcm2835-pm-wdt";
			clocks = <0x08 0x15 0x08 0x1d 0x08 0x17 0x08 0x16>;
			#reset-cells = <0x01>;
			reg-names = "pm\0asb";
			clock-names = "v3d\0peri_image\0h264\0isp";
			system-power-controller;
			phandle = <0x2c>;
			reg = <0x7e100000 0x114 0x7e00a000 0x24>;
			#power-domain-cells = <0x01>;
		};

		interrupt-controller@7e00b200 {
			compatible = "brcm,bcm2836-armctrl-ic";
			#interrupt-cells = <0x02>;
			interrupt-parent = <0x18>;
			interrupts = <0x08 0x04>;
			phandle = <0x01>;
			reg = <0x7e00b200 0x200>;
			interrupt-controller;
		};

		aux@7e215000 {
			compatible = "brcm,bcm2835-aux";
			clocks = <0x08 0x14>;
			#clock-cells = <0x01>;
			phandle = <0x12>;
			reg = <0x7e215000 0x08>;
		};

		dsi@7e700000 {
			power-domains = <0x11 0x12>;
			compatible = "brcm,bcm2835-dsi1";
			clocks = <0x08 0x23 0x08 0x30 0x08 0x32>;
			clock-names = "phy\0escape\0pixel";
			status = "okay";
			#address-cells = <0x01>;
			interrupts = <0x02 0x0c>;
			#size-cells = <0x00>;
			#clock-cells = <0x01>;
			phandle = <0x05>;
			reg = <0x7e700000 0x8c>;
			clock-output-names = "dsi1_byte\0dsi1_ddr2\0dsi1_ddr";

			port {

				endpoint {
					remote-endpoint = <0x98>;
					phandle = <0x9a>;
				};
			};

			bridge@0 {
				compatible = "toshiba,tc358762";
				vddc-supply = <0x99>;
				reg = <0x00>;

				ports {
					#address-cells = <0x01>;
					#size-cells = <0x00>;

					port@1 {
						reg = <0x01>;

						endpoint {
							remote-endpoint = <0x9b>;
							phandle = <0x9d>;
						};
					};

					port@0 {
						reg = <0x00>;

						endpoint {
							remote-endpoint = <0x9a>;
							phandle = <0x98>;
						};
					};
				};
			};
		};

		axiperf {
			compatible = "brcm,bcm2835-axiperf";
			firmware = <0x06>;
			status = "disabled";
			phandle = <0x31>;
			reg = <0x7e009800 0x100 0x7ee08000 0x100>;
		};

		sound {
			status = "disabled";
			phandle = <0x8c>;
		};

		i2c@7e205000 {
			compatible = "brcm,bcm2835-i2c";
			clocks = <0x08 0x14>;
			status = "okay";
			#address-cells = <0x01>;
			interrupts = <0x02 0x15>;
			#size-cells = <0x00>;
			phandle = <0x1c>;
			reg = <0x7e205000 0x200>;
			clock-frequency = <0x186a0>;
		};

		txp@7e004000 {
			compatible = "brcm,bcm2835-txp";
			status = "okay";
			interrupts = <0x01 0x0b>;
			phandle = <0x3e>;
			reg = <0x7e004000 0x20>;
		};

		serial@7e215040 {
			compatible = "brcm,bcm2835-aux-uart";
			clocks = <0x12 0x00>;
			status = "disabled";
			interrupts = <0x01 0x1d>;
			skip-init;
			phandle = <0x27>;
			reg = <0x7e215040 0x40>;
			pinctrl-0 = <0x13>;
			pinctrl-names = "default";

			bluetooth {
				compatible = "brcm,bcm43438-bt";
				shutdown-gpios = <0x0b 0x00 0x00>;
				max-speed = <0x70800>;
				status = "disabled";
				phandle = <0x75>;
			};
		};

		dma@7e007000 {
			#dma-cells = <0x01>;
			compatible = "brcm,bcm2835-dma";
			brcm,dma-channel-mask = <0x7f35>;
			interrupts = <0x01 0x10 0x01 0x11 0x01 0x12 0x01 0x13 0x01 0x14 0x01 0x15 0x01 0x16 0x01 0x17 0x01 0x18 0x01 0x19 0x01 0x1a 0x01 0x1b 0x01 0x1b 0x01 0x1b 0x01 0x1b 0x01 0x1c>;
			phandle = <0x0c>;
			reg = <0x7e007000 0xf00>;
			interrupt-names = "dma0\0dma1\0dma2\0dma3\0dma4\0dma5\0dma6\0dma7\0dma8\0dma9\0dma10\0dma11\0dma12\0dma13\0dma14\0dma-shared-all";
		};

		i2c@7e805000 {
			compatible = "brcm,bcm2835-i2c";
			clocks = <0x08 0x14>;
			status = "okay";
			#address-cells = <0x01>;
			interrupts = <0x02 0x15>;
			#size-cells = <0x00>;
			phandle = <0x1a>;
			reg = <0x7e805000 0x1000>;
			clock-frequency = <0x186a0>;
		};

		spi@7e215080 {
			compatible = "brcm,bcm2835-aux-spi";
			clocks = <0x12 0x01>;
			status = "disabled";
			#address-cells = <0x01>;
			interrupts = <0x01 0x1d>;
			#size-cells = <0x00>;
			phandle = <0x76>;
			reg = <0x7e215080 0x40>;
		};

		firmwarekms@7e600000 {
			compatible = "raspberrypi,rpi-firmware-kms";
			status = "disabled";
			interrupts = <0x02 0x10>;
			brcm,firmware = <0x06>;
			phandle = <0x83>;
			reg = <0x7e600000 0x100>;
		};

		rng@7e104000 {
			compatible = "brcm,bcm2835-rng";
			interrupts = <0x02 0x1d>;
			phandle = <0x2d>;
			reg = <0x7e104000 0x10>;
		};

		usb@7e980000 {
			power-domains = <0x11 0x06>;
			compatible = "brcm,bcm2708-usb";
			clocks = <0x16>;
			clock-names = "otg";
			phy-names = "usb2-phy";
			#address-cells = <0x01>;
			interrupts = <0x01 0x09 0x02 0x00>;
			#size-cells = <0x00>;
			phandle = <0x7a>;
			phys = <0x17>;
			reg = <0x7e980000 0x10000 0x7e006000 0x1000>;
			interrupt-names = "usb\0soft";

			usb1@1 {
				compatible = "usb424,9514";
				#address-cells = <0x01>;
				#size-cells = <0x00>;
				reg = <0x01>;

				ethernet@1 {
					compatible = "usb424,ec00";
					local-mac-address = [b8 27 eb c1 59 e7];
					phandle = <0x7b>;
					reg = <0x01>;
				};
			};
		};

		smi@7e600000 {
			compatible = "brcm,bcm2835-smi";
			clocks = <0x08 0x2a>;
			status = "disabled";
			interrupts = <0x02 0x10>;
			assigned-clock-rates = <0x7735940>;
			dma-names = "rx-tx";
			assigned-clocks = <0x08 0x2a>;
			phandle = <0x84>;
			reg = <0x7e600000 0x100>;
			dmas = <0x0c 0x04>;
		};

		spi@7e2150c0 {
			compatible = "brcm,bcm2835-aux-spi";
			clocks = <0x12 0x02>;
			status = "disabled";
			#address-cells = <0x01>;
			interrupts = <0x01 0x1d>;
			#size-cells = <0x00>;
			phandle = <0x77>;
			reg = <0x7e2150c0 0x40>;
		};
	};

	leds {
		compatible = "gpio-leds";
		phandle = <0x93>;

		led-act {
			gpios = <0x37 0x00 0x00>;
			label = "ACT";
			phandle = <0x35>;
			default-state = "off";
			linux,default-trigger = "mmc0";
		};

		led-pwr {
			gpios = <0x0b 0x07 0x00>;
			label = "PWR";
			phandle = <0x36>;
			default-state = "off";
			linux,default-trigger = "input";
		};
	};

	cam_dummy_reg {
		compatible = "regulator-fixed";
		status = "okay";
		phandle = <0x92>;
		regulator-name = "cam-dummy-reg";
	};

	aliases {
		display0 = "/chosen/framebuffer@3ea81000";
		intc = "/soc/interrupt-controller@7e00b200";
		i2c10 = "/soc/i2c0mux/i2c@1";
		spi2 = "/soc/spi@7e2150c0";
		i2c1 = "/soc/i2c@7e804000";
		i2c_vc = "/soc/i2c0mux/i2c@0";
		spi0 = "/soc/spi@7e204000";
		thermal = "/soc/thermal@7e212000";
		sdhost = "/soc/mmc@7e202000";
		aux = "/soc/aux@7e215000";
		gpio = "/soc/gpio@7e200000";
		mmc1 = "/soc/mmcnr@7e300000";
		dma = "/soc/dma@7e007000";
		ethernet0 = "/soc/usb@7e980000/usb1@1/ethernet@1";
		soc = "/soc";
		leds = "/leds";
		mmc = "/soc/mmc@7e300000";
		serial1 = "/soc/serial@7e201000";
		i2c_arm = "/soc/i2c@7e804000";
		uart0 = "/soc/serial@7e201000";
		fb = "/soc/fb";
		i2c2 = "/soc/i2c@7e805000";
		i2s = "/soc/i2s@7e203000";
		spi1 = "/soc/spi@7e215080";
		usb = "/soc/usb@7e980000";
		i2c0 = "/soc/i2c0mux/i2c@0";
		watchdog = "/soc/watchdog@7e100000";
		axiperf = "/soc/axiperf";
		mmc0 = "/soc/mmc@7e202000";
		sound = "/soc/sound";
		mailbox = "/soc/mailbox@7e00b880";
		uart1 = "/soc/serial@7e215040";
		random = "/soc/rng@7e104000";
		i2c = "/soc/i2c@7e804000";
		serial0 = "/soc/serial@7e215040";
	};

	chosen {
		compatible = "simple_bus";
		bootargs = "coherent_pool=1M 8250.nr_uarts=0 snd_bcm2835.enable_headphones=0 snd_bcm2835.enable_headphones=1 snd_bcm2835.enable_hdmi=1 snd_bcm2835.enable_hdmi=0 video=HDMI-A-1:1920x1080M@60 vc_mem.mem_base=0x3ec00000 vc_mem.mem_size=0x40000000  console=ttyS0,115200 console=tty1 root=PARTUUID=f97ad7c7-02 rootfstype=ext4 fsck.repair=yes rootwait quiet splash plymouth.ignore-serial-consoles";
		rpi-boardrev-ext = <0x00>;
		ranges;
		log = <0x3ff80000 0x7ffe0>;
		#address-cells = <0x01>;
		#size-cells = <0x01>;
		phandle = <0x34>;
		os_prefix;
		overlay_prefix = [6f 76 65 72 6c 61 79 73 2f];
		kaslr-seed = <0xba619308 0x84678d86>;

		bootloader {
			boot-mode = <0x01>;
			partition = <0x00>;
			rsts = <0x1000>;
			tryboot = <0x00>;
		};

		framebuffer@3ea81000 {
			compatible = "simple-framebuffer";
			width = <0x320>;
			stride = <0xc80>;
			status = "okay";
			reg = <0x3ea81000 0x177000>;
			format = "a8r8g8b8";
			height = <0x1e0>;
		};
	};

	thermal-zones {

		cpu-thermal {
			thermal-sensors = <0x02>;
			polling-delay = <0x3e8>;
			polling-delay-passive = <0x00>;
			coefficients = <0xfffffde6 0x64960>;
			phandle = <0x3a>;

			trips {
				phandle = <0x3b>;

				cpu-crit {
					hysteresis = <0x00>;
					temperature = <0x1adb0>;
					type = "critical";
				};
			};

			cooling-maps {
				phandle = <0x3c>;
			};
		};
	};

	cam1_regulator {
		compatible = "regulator-fixed";
		enable-active-high;
		gpio = <0x0b 0x05 0x00>;
		status = "okay";
		phandle = <0x8e>;
		regulator-name = "cam1-reg";
	};

	cam1_clk {
		compatible = "fixed-clock";
		status = "disabled";
		#clock-cells = <0x00>;
		phandle = <0x8f>;
	};

	timer {
		compatible = "arm,armv7-timer";
		always-on;
		interrupt-parent = <0x18>;
		interrupts = <0x00 0x04 0x01 0x04 0x03 0x04 0x02 0x04>;
	};

	phy {
		compatible = "usb-nop-xceiv";
		phandle = <0x17>;
		#phy-cells = <0x00>;
	};

	fixedregulator_3v3 {
		compatible = "regulator-fixed";
		phandle = <0x94>;
		regulator-min-microvolt = <0x325aa0>;
		regulator-max-microvolt = <0x325aa0>;
		regulator-always-on;
		regulator-name = "3v3";
	};

	cpus {
		enable-method = "brcm,bcm2836-smp";
		#address-cells = <0x01>;
		#size-cells = <0x00>;
		phandle = <0x8d>;

		cpu@3 {
			compatible = "arm,cortex-a53";
			cpu-release-addr = <0x00 0xf0>;
			device_type = "cpu";
			i-cache-line-size = <0x40>;
			next-level-cache = <0x21>;
			enable-method = "spin-table";
			phandle = <0x25>;
			reg = <0x03>;
			clock-frequency = <0x47868c00>;
			d-cache-size = <0x8000>;
			i-cache-size = <0x8000>;
			d-cache-sets = <0x80>;
			i-cache-sets = <0x100>;
			d-cache-line-size = <0x40>;
		};

		cpu@1 {
			compatible = "arm,cortex-a53";
			cpu-release-addr = <0x00 0xe0>;
			device_type = "cpu";
			i-cache-line-size = <0x40>;
			next-level-cache = <0x21>;
			enable-method = "spin-table";
			phandle = <0x23>;
			reg = <0x01>;
			clock-frequency = <0x47868c00>;
			d-cache-size = <0x8000>;
			i-cache-size = <0x8000>;
			d-cache-sets = <0x80>;
			i-cache-sets = <0x100>;
			d-cache-line-size = <0x40>;
		};

		cpu@2 {
			compatible = "arm,cortex-a53";
			cpu-release-addr = <0x00 0xe8>;
			device_type = "cpu";
			i-cache-line-size = <0x40>;
			next-level-cache = <0x21>;
			enable-method = "spin-table";
			phandle = <0x24>;
			reg = <0x02>;
			clock-frequency = <0x47868c00>;
			d-cache-size = <0x8000>;
			i-cache-size = <0x8000>;
			d-cache-sets = <0x80>;
			i-cache-sets = <0x100>;
			d-cache-line-size = <0x40>;
		};

		l2-cache0 {
			compatible = "cache";
			cache-level = <0x02>;
			cache-line-size = <0x40>;
			phandle = <0x21>;
			cache-size = <0x80000>;
			cache-sets = <0x200>;
		};

		cpu@0 {
			compatible = "arm,cortex-a53";
			cpu-release-addr = <0x00 0xd8>;
			device_type = "cpu";
			i-cache-line-size = <0x40>;
			next-level-cache = <0x21>;
			enable-method = "spin-table";
			phandle = <0x22>;
			reg = <0x00>;
			clock-frequency = <0x47868c00>;
			d-cache-size = <0x8000>;
			i-cache-size = <0x8000>;
			d-cache-sets = <0x80>;
			i-cache-sets = <0x100>;
			d-cache-line-size = <0x40>;
		};
	};

	fixedregulator_5v0 {
		compatible = "regulator-fixed";
		phandle = <0x95>;
		regulator-min-microvolt = <0x4c4b40>;
		regulator-max-microvolt = <0x4c4b40>;
		regulator-always-on;
		regulator-name = "5v0";
	};

	axi {

		vc_mem {
			reg = <0x3ec00000 0x40000000 0xc0000000>;
		};
	};
};
